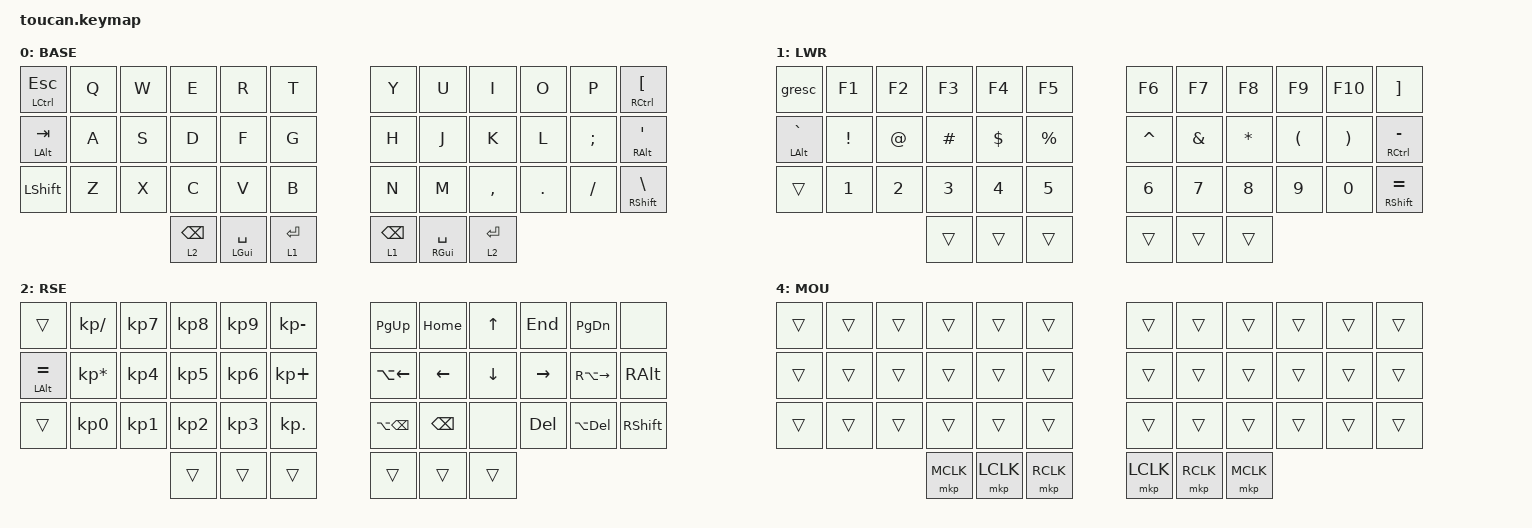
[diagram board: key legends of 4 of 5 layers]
#include <behaviors.dtsi>
#include <dt-bindings/zmk/bt.h>
#include <dt-bindings/zmk/keys.h>
#include <dt-bindings/zmk/pointing.h>

#define DEF 0
#define LWR 1
#define RSE 2
#define ADJ 3
// Layer 4 is held automatically while a finger rests on the trackpad,
// see `is_touching_processor` in boards/shields/toucan/toucan.dtsi
#define MOU 4

&lt {
    quick-tap-ms = <200>;
};

&mt {
    quick-tap-ms = <200>;
};

/ {
    behaviors {
        // Destructive actions: only fire after a two second hold, a short tap does nothing.
        hold_bt_clr: hold_bt_clr {
            compatible = "zmk,behavior-hold-tap";
            #binding-cells = <2>;
            flavor = "tap-preferred";
            tapping-term-ms = <2000>;
            bindings = <&bt>, <&none>;
        };

        hold_boot: hold_boot {
            compatible = "zmk,behavior-hold-tap";
            #binding-cells = <2>;
            flavor = "tap-preferred";
            tapping-term-ms = <2000>;
            bindings = <&bootloader>, <&none>;
        };

        hold_reset: hold_reset {
            compatible = "zmk,behavior-hold-tap";
            #binding-cells = <2>;
            flavor = "tap-preferred";
            tapping-term-ms = <2000>;
            bindings = <&sys_reset>, <&none>;
        };
    };

    conditional_layers {
        compatible = "zmk,conditional-layers";

        tri_layer {
            if-layers = <1 2>;
            then-layer = <3>;
        };
    };

    keymap {
        compatible = "zmk,keymap";

        default_layer {
            display-name = "BASE";
            bindings = <
&mt LCTRL ESC     &kp Q  &kp W  &kp E            &kp R               &kp T      &kp Y            &kp U                &kp I      &kp O    &kp P     &mt RIGHT_CONTROL LBKT
&mt LEFT_ALT TAB  &kp A  &kp S  &kp D            &kp F               &kp G      &kp H            &kp J                &kp K      &kp L    &kp SEMI  &mt RIGHT_ALT SQT
&kp LEFT_SHIFT    &kp Z  &kp X  &kp C            &kp V               &kp B      &kp N            &kp M                &kp COMMA  &kp DOT  &kp FSLH  &mt RIGHT_SHIFT BSLH
                                &lt 2 BACKSPACE  &mt LEFT_GUI SPACE  &lt 1 RET  &lt 1 BACKSPACE  &mt RIGHT_GUI SPACE  &lt 2 RET
            >;
        };

        lower_layer {
            display-name = "LWR";
            bindings = <
&gresc              &kp F1    &kp F2  &kp F3    &kp F4    &kp F5     &kp F6     &kp F7    &kp F8    &kp F9    &kp F10   &kp RIGHT_BRACKET
&mt LEFT_ALT GRAVE  &kp EXCL  &kp AT  &kp HASH  &kp DLLR  &kp PRCNT  &kp CARET  &kp AMPS  &kp STAR  &kp LPAR  &kp RPAR  &mt RCTRL MINUS
&trans              &kp N1    &kp N2  &kp N3    &kp N4    &kp N5     &kp N6     &kp N7    &kp N8    &kp N9    &kp N0    &mt RIGHT_SHIFT EQUAL
                                      &trans    &trans    &trans     &trans     &trans    &trans
            >;
        };

        raise_layer {
            display-name = "RSE";
            bindings = <
&trans              &kp KP_SLASH     &kp KP_N7  &kp KP_N8  &kp KP_N9  &kp KP_MINUS  &kp PG_UP          &kp HOME       &kp UP    &kp END     &kp PAGE_DOWN   &none
&mt LEFT_ALT EQUAL  &kp KP_MULTIPLY  &kp KP_N4  &kp KP_N5  &kp KP_N6  &kp KP_PLUS   &kp LA(LEFT)       &kp LEFT       &kp DOWN  &kp RIGHT   &kp RA(RIGHT)   &kp RIGHT_ALT
&trans              &kp KP_N0        &kp KP_N1  &kp KP_N2  &kp KP_N3  &kp KP_DOT    &kp LA(BACKSPACE)  &kp BACKSPACE  &none     &kp DELETE  &kp LA(DELETE)  &kp RIGHT_SHIFT
                                                &trans     &trans     &trans        &trans             &trans         &trans
            >;
        };

        adjust_layer {
            display-name = "ADJ";
            bindings = <
&hold_boot 0 0   &kp RS(RA(RC(RG(Q))))  &kp RS(RA(RC(RG(W))))  &kp RS(RA(RC(RG(E))))  &kp RS(RA(RC(RG(R))))  &kp RS(RA(RC(RG(T))))  &studio_unlock  &kp C_VOL_DN  &kp C_MUTE  &kp C_VOL_UP  &kp F11  &kp F12
&none            &kp RS(RA(RC(RG(A))))  &kp RS(RA(RC(RG(S))))  &kp RS(RA(RC(RG(D))))  &kp RS(RA(RC(RG(F))))  &kp RS(RA(RC(RG(G))))  &bt BT_SEL 2    &kp F17       &kp F18     &kp F19       &kp F20  &hold_bt_clr BT_CLR
&hold_reset 0 0  &kp RS(RA(RC(RG(Z))))  &kp RS(RA(RC(RG(X))))  &kp RS(RA(RC(RG(C))))  &kp RS(RA(RC(RG(V))))  &kp RS(RA(RC(RG(B))))  &bt BT_SEL 0    &kp F21       &kp F22     &kp F23       &kp F24  &hold_reset 0 0
                                                               &trans                 &trans                 &trans                 &trans          &trans        &trans
            >;
        };

        mouse {
            display-name = "MOU";
            bindings = <
&trans  &trans  &trans  &trans     &trans     &trans     &trans     &trans     &trans     &trans  &trans  &trans
&trans  &trans  &trans  &trans     &trans     &trans     &trans     &trans     &trans     &trans  &trans  &trans
&trans  &trans  &trans  &trans     &trans     &trans     &trans     &trans     &trans     &trans  &trans  &trans
                        &mkp MCLK  &mkp LCLK  &mkp RCLK  &mkp LCLK  &mkp RCLK  &mkp MCLK
            >;
        };

        extra_2 { status = "reserved"; };

        extra_3 { status = "reserved"; };
    };
};
